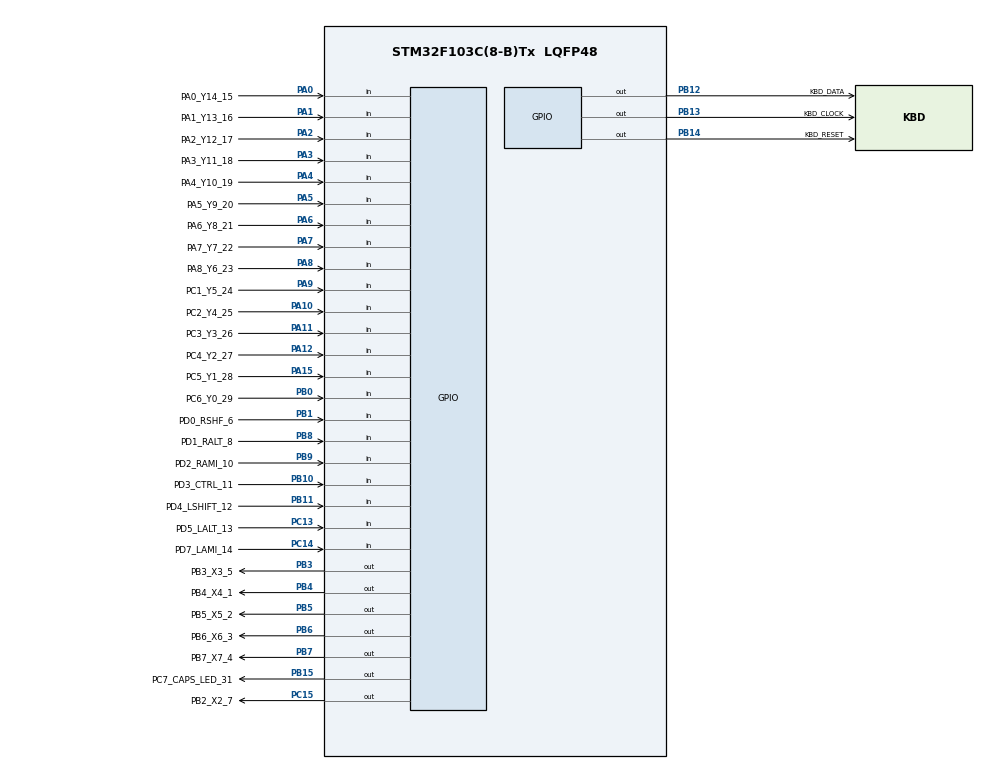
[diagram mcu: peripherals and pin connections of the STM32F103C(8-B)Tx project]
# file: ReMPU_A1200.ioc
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Mcu.Family=STM32F1
Mcu.Name=STM32F103C(8-B)Tx
Mcu.Package=LQFP48
NVIC.PriorityGroup=NVIC_PRIORITYGROUP_4
PA0-WKUP.GPIO_Label=PA0_Y14_15
PA0-WKUP.GPIO_PuPd=GPIO_PULLUP
PA0-WKUP.Signal=GPIO_Input
PA1.GPIO_Label=PA1_Y13_16
PA1.GPIO_PuPd=GPIO_PULLUP
PA1.Signal=GPIO_Input
PA10.GPIO_Label=PC2_Y4_25
PA10.GPIO_PuPd=GPIO_PULLUP
PA10.Signal=GPIO_Input
PA11.GPIO_Label=PC3_Y3_26
PA11.GPIO_PuPd=GPIO_PULLUP
PA11.Signal=GPIO_Input
PA12.GPIO_Label=PC4_Y2_27
PA12.GPIO_PuPd=GPIO_PULLUP
PA12.Signal=GPIO_Input
PA13.Mode=Serial_Wire
PA13.Signal=SYS_JTMS-SWDIO
PA14.Mode=Serial_Wire
PA14.Signal=SYS_JTCK-SWCLK
PA15.GPIO_Label=PC5_Y1_28
PA15.GPIO_PuPd=GPIO_PULLUP
PA15.Signal=GPIO_Input
PA2.GPIO_Label=PA2_Y12_17
PA2.GPIO_PuPd=GPIO_PULLUP
PA2.Signal=GPIO_Input
PA3.GPIO_Label=PA3_Y11_18
PA3.GPIO_PuPd=GPIO_PULLUP
PA3.Signal=GPIO_Input
PA4.GPIO_Label=PA4_Y10_19
PA4.GPIO_PuPd=GPIO_PULLUP
PA4.Signal=GPIO_Input
PA5.GPIO_Label=PA5_Y9_20
PA5.GPIO_PuPd=GPIO_PULLUP
PA5.Signal=GPIO_Input
PA6.GPIO_Label=PA6_Y8_21
PA6.GPIO_PuPd=GPIO_PULLUP
PA6.Signal=GPIO_Input
PA7.GPIO_Label=PA7_Y7_22
PA7.GPIO_PuPd=GPIO_PULLUP
PA7.Signal=GPIO_Input
PA8.GPIO_Label=PA8_Y6_23
PA8.GPIO_PuPd=GPIO_PULLUP
PA8.Signal=GPIO_Input
PA9.GPIO_Label=PC1_Y5_24
PA9.GPIO_PuPd=GPIO_PULLUP
PA9.Signal=GPIO_Input
PB0.GPIO_Label=PC6_Y0_29
PB0.GPIO_PuPd=GPIO_PULLUP
PB0.Signal=GPIO_Input
PB1.GPIO_Label=PD0_RSHF_6
PB1.GPIO_PuPd=GPIO_PULLUP
PB1.Signal=GPIO_Input
PB10.GPIO_Label=PD3_CTRL_11
PB10.GPIO_PuPd=GPIO_PULLUP
PB10.Signal=GPIO_Input
PB11.GPIO_Label=PD4_LSHIFT_12
PB11.GPIO_PuPd=GPIO_PULLUP
PB11.Signal=GPIO_Input
PB12.GPIO_Label=KBD_DATA
PB12.Signal=GPIO_Output
PB13.GPIO_Label=KBD_CLOCK
PB13.Signal=GPIO_Output
PB14.GPIO_Label=KBD_RESET
PB14.Signal=GPIO_Output
PB15.GPIO_Label=PC7_CAPS_LED_31
PB15.GPIO_ModeDefaultOutputPP=GPIO_MODE_OUTPUT_OD
PB15.GPIO_PuPd=GPIO_NOPULL
PB15.PinState=GPIO_PIN_RESET
PB15.Signal=GPIO_Output
PB3.GPIO_Label=PB3_X3_5
PB3.GPIO_ModeDefaultOutputPP=GPIO_MODE_OUTPUT_OD
PB3.GPIO_PuPd=GPIO_PULLUP
PB3.PinState=GPIO_PIN_SET
PB3.Signal=GPIO_Output
PB4.GPIO_Label=PB4_X4_1
PB4.GPIO_PuPd=GPIO_PULLUP
PB4.PinState=GPIO_PIN_SET
PB4.Signal=GPIO_Output
PB5.GPIO_Label=PB5_X5_2
PB5.GPIO_ModeDefaultOutputPP=GPIO_MODE_OUTPUT_OD
PB5.GPIO_PuPd=GPIO_PULLUP
PB5.PinState=GPIO_PIN_SET
PB5.Signal=GPIO_Output
PB6.GPIO_Label=PB6_X6_3
PB6.GPIO_ModeDefaultOutputPP=GPIO_MODE_OUTPUT_OD
PB6.GPIO_PuPd=GPIO_PULLUP
PB6.PinState=GPIO_PIN_SET
PB6.Signal=GPIO_Output
PB7.GPIO_Label=PB7_X7_4
PB7.GPIO_ModeDefaultOutputPP=GPIO_MODE_OUTPUT_OD
PB7.GPIO_PuPd=GPIO_PULLUP
PB7.PinState=GPIO_PIN_SET
PB7.Signal=GPIO_Output
PB8.GPIO_Label=PD1_RALT_8
PB8.GPIO_PuPd=GPIO_PULLUP
PB8.Signal=GPIO_Input
PB9.GPIO_Label=PD2_RAMI_10
PB9.GPIO_PuPd=GPIO_PULLUP
PB9.Signal=GPIO_Input
PC13-TAMPER-RTC.GPIO_Label=PD5_LALT_13
PC13-TAMPER-RTC.Signal=GPIO_Input
PC14-OSC32_IN.GPIO_Label=PD7_LAMI_14
PC14-OSC32_IN.GPIO_PuPd=GPIO_PULLUP
PC14-OSC32_IN.Signal=GPIO_Input
PC15-OSC32_OUT.GPIO_Label=PB2_X2_7
PC15-OSC32_OUT.GPIO_ModeDefaultOutputPP=GPIO_MODE_OUTPUT_OD
PC15-OSC32_OUT.GPIO_PuPd=GPIO_PULLUP
PC15-OSC32_OUT.PinState=GPIO_PIN_SET
PC15-OSC32_OUT.Signal=GPIO_Output
ProjectManager.HeapSize=0x200
ProjectManager.StackSize=0x400
ProjectManager.TargetToolchain=STM32CubeIDE
RCC.APB1Freq_Value=8000000
RCC.APB2Freq_Value=8000000
board=custom

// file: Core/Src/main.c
/* USER CODE BEGIN Header */
/**
  ******************************************************************************
  * @file           : main.c
  * @brief          : Main program body
  ******************************************************************************
  * @attention
  *
  * <h2><center>&copy; Copyright (c) 2020 STMicroelectronics.
  * All rights reserved.</center></h2>
  *
  * This software component is licensed by ST under BSD 3-Clause license,
  * the "License"; You may not use this file except in compliance with the
  * License. You may obtain a copy of the License at:
  *                        opensource.org/licenses/BSD-3-Clause
  *
  ******************************************************************************
  */
/* USER CODE END Header */

#include "main.h"

/* USER CODE BEGIN Includes */
#include "keyboard.h"
#include "amiga.h"
#include "dwt_delay.h"
#include <string.h>

/* USER CODE END Includes */

/* USER CODE BEGIN PV */
    keyboard_t keyboard;

/* USER CODE END PV */

void SystemClock_Config(void);
static void MX_GPIO_Init(void);

int main(void)
{

  /* MCU Configuration--------------------------------------------------------*/

  /* Reset of all peripherals, Initializes the Flash interface and the Systick. */
  HAL_Init();

  /* Configure the system clock */
  SystemClock_Config();

  /* Initialize all configured peripherals */
  MX_GPIO_Init();
  /* USER CODE BEGIN 2 */
  DWT_Init();

  amikb_startup();
  keyboard_t keyboard;

  /* USER CODE END 2 */

  /* Infinite loop */
  while (1)
  {

    /* USER CODE BEGIN 3 */

	  //clear
	  memset(&keyboard,0,sizeof(keyboard));

	  //As there is amiga code for 0x00 other value is requried to mark entry as empty.
	  memset(&keyboard.keyboard_codes,0xFF,sizeof(keyboard.keyboard_codes));
	  //
	  memset(&keyboard.special_keys,0xFF,sizeof(keyboard.special_keys));
	  ProcessKeyboard(&keyboard);
	  amikb_process(&keyboard);
  }
  /* USER CODE END 3 */
}

void SystemClock_Config(void)
{
  RCC_OscInitTypeDef RCC_OscInitStruct = {0};
  RCC_ClkInitTypeDef RCC_ClkInitStruct = {0};

  /** Initializes the CPU, AHB and APB busses clocks
  */
  RCC_OscInitStruct.OscillatorType = RCC_OSCILLATORTYPE_HSI;
  RCC_OscInitStruct.HSIState = RCC_HSI_ON;
  RCC_OscInitStruct.HSICalibrationValue = RCC_HSICALIBRATION_DEFAULT;
  RCC_OscInitStruct.PLL.PLLState = RCC_PLL_NONE;
  if (HAL_RCC_OscConfig(&RCC_OscInitStruct) != HAL_OK)
  {
    Error_Handler();
  }
  /** Initializes the CPU, AHB and APB busses clocks
  */
  RCC_ClkInitStruct.ClockType = RCC_CLOCKTYPE_HCLK|RCC_CLOCKTYPE_SYSCLK
                              |RCC_CLOCKTYPE_PCLK1|RCC_CLOCKTYPE_PCLK2;
  RCC_ClkInitStruct.SYSCLKSource = RCC_SYSCLKSOURCE_HSI;
  RCC_ClkInitStruct.AHBCLKDivider = RCC_SYSCLK_DIV1;
  RCC_ClkInitStruct.APB1CLKDivider = RCC_HCLK_DIV1;
  RCC_ClkInitStruct.APB2CLKDivider = RCC_HCLK_DIV1;

  if (HAL_RCC_ClockConfig(&RCC_ClkInitStruct, FLASH_LATENCY_0) != HAL_OK)
  {
    Error_Handler();
  }
}

static void MX_GPIO_Init(void)
{
  GPIO_InitTypeDef GPIO_InitStruct = {0};

  /* GPIO Ports Clock Enable */
  __HAL_RCC_GPIOC_CLK_ENABLE();
  __HAL_RCC_GPIOA_CLK_ENABLE();
  __HAL_RCC_GPIOB_CLK_ENABLE();

  /*Configure GPIO pin Output Level */
  HAL_GPIO_WritePin(PB2_X2_7_GPIO_Port, PB2_X2_7_Pin, GPIO_PIN_SET);

  /*Configure GPIO pin Output Level */
  HAL_GPIO_WritePin(GPIOB, KBD_DATA_Pin|KBD_CLOCK_Pin|KBD_RESET_Pin|PC7_CAPS_LED_31_Pin, GPIO_PIN_RESET);

  /*Configure GPIO pin Output Level */
  HAL_GPIO_WritePin(GPIOB, PB3_X3_5_Pin|PB4_X4_1_Pin|PB5_X5_2_Pin|PB6_X6_3_Pin
                          |PB7_X7_4_Pin, GPIO_PIN_SET);

  /*Configure GPIO pin : PD5_LALT_13_Pin */
  GPIO_InitStruct.Pin = PD5_LALT_13_Pin;
  GPIO_InitStruct.Mode = GPIO_MODE_INPUT;
  GPIO_InitStruct.Pull = GPIO_NOPULL;
  HAL_GPIO_Init(PD5_LALT_13_GPIO_Port, &GPIO_InitStruct);

  /*Configure GPIO pin : PD7_LAMI_14_Pin */
  GPIO_InitStruct.Pin = PD7_LAMI_14_Pin;
  GPIO_InitStruct.Mode = GPIO_MODE_INPUT;
  GPIO_InitStruct.Pull = GPIO_PULLUP;
  HAL_GPIO_Init(PD7_LAMI_14_GPIO_Port, &GPIO_InitStruct);

  /*Configure GPIO pin : PB2_X2_7_Pin */
  GPIO_InitStruct.Pin = PB2_X2_7_Pin;
  GPIO_InitStruct.Mode = GPIO_MODE_OUTPUT_OD;
  GPIO_InitStruct.Pull = GPIO_PULLUP;
  GPIO_InitStruct.Speed = GPIO_SPEED_FREQ_LOW;
  HAL_GPIO_Init(PB2_X2_7_GPIO_Port, &GPIO_InitStruct);

  /*Configure GPIO pins : PA0_Y14_15_Pin PA1_Y13_16_Pin PA2_Y12_17_Pin PA3_Y11_18_Pin
                           PA4_Y10_19_Pin PA5_Y9_20_Pin PA6_Y8_21_Pin PA7_Y7_22_Pin
                           PA8_Y6_23_Pin PC1_Y5_24_Pin PC2_Y4_25_Pin PC3_Y3_26_Pin
                           PC4_Y2_27_Pin PC5_Y1_28_Pin */
  GPIO_InitStruct.Pin = PA0_Y14_15_Pin|PA1_Y13_16_Pin|PA2_Y12_17_Pin|PA3_Y11_18_Pin
                          |PA4_Y10_19_Pin|PA5_Y9_20_Pin|PA6_Y8_21_Pin|PA7_Y7_22_Pin
                          |PA8_Y6_23_Pin|PC1_Y5_24_Pin|PC2_Y4_25_Pin|PC3_Y3_26_Pin
                          |PC4_Y2_27_Pin|PC5_Y1_28_Pin;
  GPIO_InitStruct.Mode = GPIO_MODE_INPUT;
  GPIO_InitStruct.Pull = GPIO_PULLUP;
  HAL_GPIO_Init(GPIOA, &GPIO_InitStruct);

  /*Configure GPIO pins : PC6_Y0_29_Pin PD0_RSHF_6_Pin PD3_CTRL_11_Pin PD4_LSHIFT_12_Pin
                           PD1_RALT_8_Pin PD2_RAMI_10_Pin */
  GPIO_InitStruct.Pin = PC6_Y0_29_Pin|PD0_RSHF_6_Pin|PD3_CTRL_11_Pin|PD4_LSHIFT_12_Pin
                          |PD1_RALT_8_Pin|PD2_RAMI_10_Pin;
  GPIO_InitStruct.Mode = GPIO_MODE_INPUT;
  GPIO_InitStruct.Pull = GPIO_PULLUP;
  HAL_GPIO_Init(GPIOB, &GPIO_InitStruct);

  /*Configure GPIO pins : KBD_DATA_Pin KBD_CLOCK_Pin KBD_RESET_Pin */
  GPIO_InitStruct.Pin = KBD_DATA_Pin|KBD_CLOCK_Pin|KBD_RESET_Pin;
  GPIO_InitStruct.Mode = GPIO_MODE_OUTPUT_PP;
  GPIO_InitStruct.Pull = GPIO_NOPULL;
  GPIO_InitStruct.Speed = GPIO_SPEED_FREQ_LOW;
  HAL_GPIO_Init(GPIOB, &GPIO_InitStruct);

  /*Configure GPIO pin : PC7_CAPS_LED_31_Pin */
  GPIO_InitStruct.Pin = PC7_CAPS_LED_31_Pin;
  GPIO_InitStruct.Mode = GPIO_MODE_OUTPUT_OD;
  GPIO_InitStruct.Pull = GPIO_NOPULL;
  GPIO_InitStruct.Speed = GPIO_SPEED_FREQ_LOW;
  HAL_GPIO_Init(PC7_CAPS_LED_31_GPIO_Port, &GPIO_InitStruct);

  /*Configure GPIO pins : PB3_X3_5_Pin PB5_X5_2_Pin PB6_X6_3_Pin PB7_X7_4_Pin */
  GPIO_InitStruct.Pin = PB3_X3_5_Pin|PB5_X5_2_Pin|PB6_X6_3_Pin|PB7_X7_4_Pin;
  GPIO_InitStruct.Mode = GPIO_MODE_OUTPUT_OD;
  GPIO_InitStruct.Pull = GPIO_PULLUP;
  GPIO_InitStruct.Speed = GPIO_SPEED_FREQ_LOW;
  HAL_GPIO_Init(GPIOB, &GPIO_InitStruct);

  /*Configure GPIO pin : PB4_X4_1_Pin */
  GPIO_InitStruct.Pin = PB4_X4_1_Pin;
  GPIO_InitStruct.Mode = GPIO_MODE_OUTPUT_PP;
  GPIO_InitStruct.Pull = GPIO_PULLUP;
  GPIO_InitStruct.Speed = GPIO_SPEED_FREQ_LOW;
  HAL_GPIO_Init(PB4_X4_1_GPIO_Port, &GPIO_InitStruct);

}

void Error_Handler(void)
{
}

/************************ (C) COPYRIGHT STMicroelectronics *****END OF FILE****/
